# SF32LB52x register map
File version: 1.0
CPU: CM33 r0p1, little endian, MPU, FPU, 3 interrupt priority bits
Registers are 32-bit, read-write, reset 0x0 unless marked. A register's access mark holds for its fields unless they carry their own. Offsets are from the block's base; [hi:lo] are bit positions; {n}, {i} and the like mark numbered series.

## LPSYS_AON
Base 0x40040000
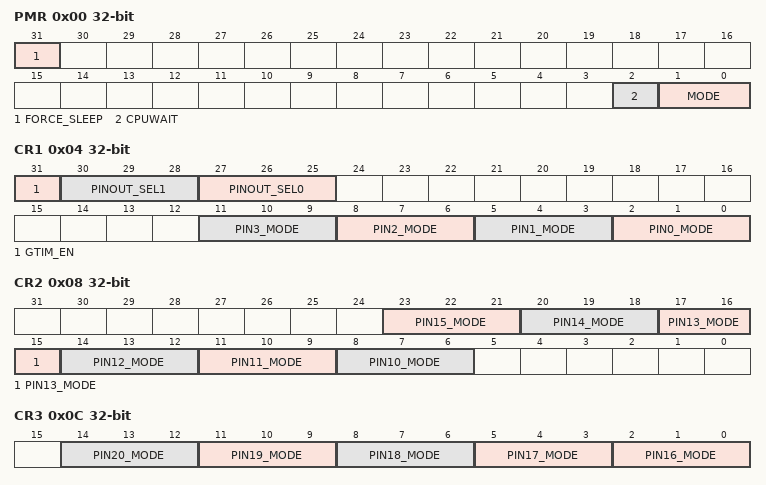
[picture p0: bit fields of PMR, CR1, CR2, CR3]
0x00 PMR — Power Mode Register
  [31] FORCE_SLEEP — Set 1 to force enter low power mode. Will be cleared automatically
  [2] CPUWAIT — Stall CPU out of reset. Should be cleared before LCPU run
  [1:0] MODE — Power Mode: 2'h0 - active/idle; 2'h1 - light sleep; 2'h2 - deep sleep; 2'h3 - standby
0x04 CR1 — Control Register 1
  [31] GTIM_EN — Enable global timer
  [30:28] PINOUT_SEL1 — for debug only
  [27:25] PINOUT_SEL0 — for debug only
  [11:9] PIN3_MODE — mode for wakeup PIN3 (PA27)
  [8:6] PIN2_MODE — mode for wakeup PIN2 (PA26)
  [5:3] PIN1_MODE — mode for wakeup PIN1 (PA25)
  [2:0] PIN0_MODE — mode for wakeup PIN0 (PA24) 0 - high level, 1 - low level, 2 - pos edge, 3 - neg edge, 4/5/6/7: pos or neg edge
0x08 CR2 — Control Register 2
  [3n-22:3n-24] PIN{n}_MODE (n=11..15) — mode for wakeup PIN{n} (PA{n+24})
  [8:6] PIN10_MODE — mode for wakeup PIN10 (PA34) 0 - high level, 1 - low level, 2 - pos edge, 3 - neg edge, 4/5/6/7: pos or neg edge
0x0C CR3 — Control Register 3
  [3n-46:3n-48] PIN{n}_MODE (n=17..20) — mode for wakeup PIN{n} (PA{n+24})
  [2:0] PIN16_MODE — mode for wakeup PIN16 (PA40) 0 - high level, 1 - low level, 2 - pos edge, 3 - neg edge, 4/5/6/7: pos or neg edge
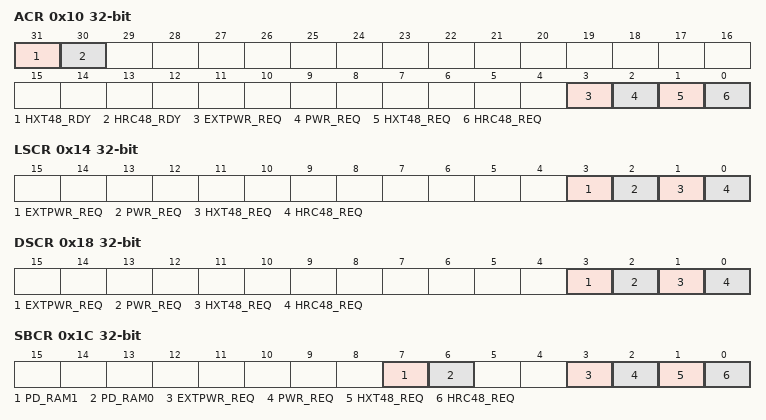
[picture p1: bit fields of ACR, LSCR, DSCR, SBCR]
0x10 ACR — Active Mode Control register
  [31] HXT48_RDY — Indicate hxt48 is ready
  [30] HRC48_RDY — Indicate hrc48 is ready
  [3] EXTPWR_REQ — for debug only
  [2] PWR_REQ — Request power during Active mode
  [1] HXT48_REQ — Request hxt48 in active mode
  [0] HRC48_REQ — Request hrc48 in active mode
0x14 LSCR — Light Sleep Ctrl Register
  [3] EXTPWR_REQ — for debug only
  [2] PWR_REQ — Request power during Light Sleep mode
  [1] HXT48_REQ — Request hxt48 in Light Sleep mode
  [0] HRC48_REQ — Request hrc48 in Light Sleep mode
0x18 DSCR — Deep Sleep Ctrl Register
  [3] EXTPWR_REQ — for debug only
  [2] PWR_REQ — Request power during Deep Sleep mode
  [1] HXT48_REQ — Request hxt48 in Deep Sleep mode
  [0] HRC48_REQ — Request hrc48 in Deep Sleep mode
0x1C SBCR — Standby Mode Ctrl Register
  [7] PD_RAM1 — for debug only
  [6] PD_RAM0 — for debug only
  [3] EXTPWR_REQ — for debug only
  [2] PWR_REQ — Request power during Standby mode
  [1] HXT48_REQ — Request hxt48 in Standby mode
  [0] HRC48_REQ — Request hrc48 in Standby mode
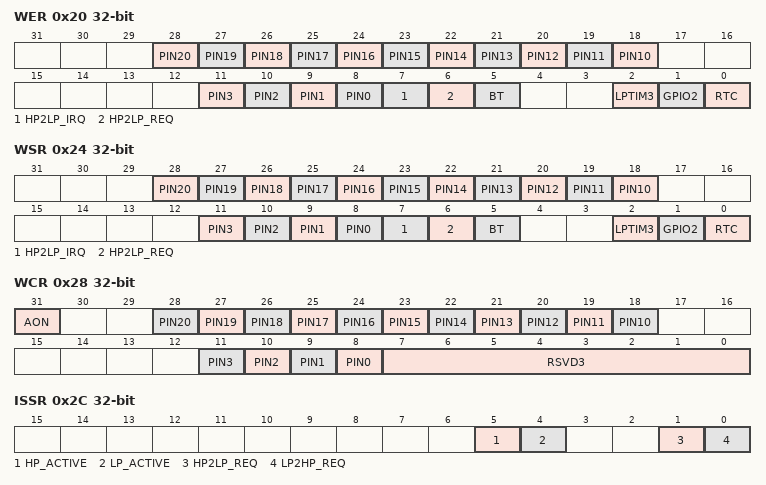
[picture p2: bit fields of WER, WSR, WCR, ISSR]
0x20 WER — Wakeup Enable register
  [n+8] PIN{n} (n=10..20) — Set 1 to enable PA{n+24} as wakeup source
  [n+8] PIN{n} (n=0..3) — Set 1 to enable PA{n+24} as wakeup source
  [7] HP2LP_IRQ — Set 1 to enable MAILBOX1 as wakeup source
  [6] HP2LP_REQ — Set 1 to enable HPSYS request as wakeup source
  [5] BT — Set 1 to enable BT as wakeup source
  [2] LPTIM3 — Set 1 to enable LPTIM3 as wakeup source
  [1] GPIO2 — Set 1 to enable IO(PB) as wakeup source
  [0] RTC — Set 1 to enable RTC as wakeup source
0x24 WSR — Wakeup Status register
  [n+8] PIN{n} (n=10..20) — Indicates the wakeup status from PA{n+24} request. Note: the status is masked by WER
  [n+8] PIN{n} (n=0..3) — Indicates the wakeup status from PA{n+24} request. Note: the status is masked by WER
  [7] HP2LP_IRQ — Indicates the wakeup status from MAILBOX1. Note: the status is masked by WER
  [6] HP2LP_REQ — Indicates the wakeup status from HPSYS request. Note: the status is masked by WER
  [5] BT — Indicates the wakeup status from BT. Note: the status is masked by WER
  [2] LPTIM3 — Indicates the wakeup status from LPTIM3. Note: the status is masked by WER
  [1] GPIO2 — Indicates the wakeup status from IO(PB). Note: the status is masked by WER
  [0] RTC — Indicates the wakeup status from RTC. Note: the status is masked by WER
0x28 WCR — Wakeup Clear register
  [31] AON — Write 1 to clear the AON wakeup IRQ status
  [n+8] PIN{n} (n=10..20) — Write 1 to clear PA{n+24} wakeup source. Only valid if PIN wakeup is configured as edge trigger
  [n+8] PIN{n} (n=0..3) — Write 1 to clear PA{n+24} wakeup source. Only valid if PIN wakeup is configured as edge trigger
  [7:0] RSVD3 — Note: for RTC/GPIO/LPTIM/BT, clear the wakeup status directly in the corresponding module
0x2C ISSR — Inter System Status Register
  [5] HP_ACTIVE — read 1 indicates HPSYS is active
  [4] LP_ACTIVE — write 1 to indicates LPSYS is active
  [1] HP2LP_REQ — indicate HPSYS request exists
  [0] LP2HP_REQ — write 1 to request HPSYS to stay in active mode
0x30 TARGET — BT sleep time target
  [27:0] SLEEP_TARGET — bt sleep time target in cycles of clk_rtc
0x34 ACTUAL — BT actual sleep time
  [27:0] SLEEP_CNT — bt actual sleep time in cycles of clk_rtc. If not woken up by software or external interrupt, sleep_cnt counts up every clk_rtc cycle, until reaches sleep_target
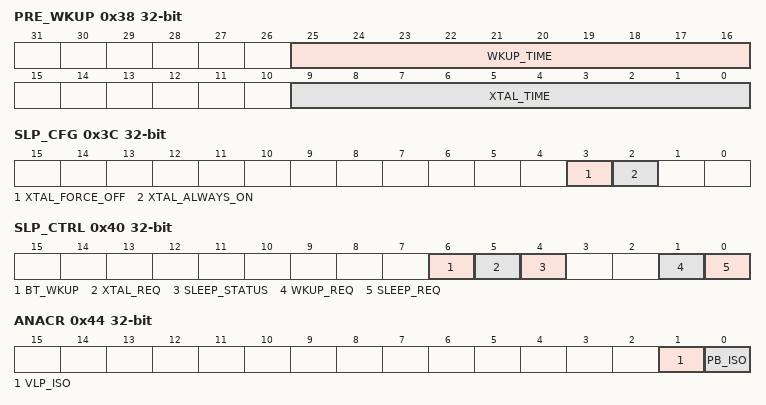
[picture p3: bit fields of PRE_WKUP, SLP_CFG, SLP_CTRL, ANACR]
0x38 PRE_WKUP — time before bt awake
  [25:16] WKUP_TIME — cycles of clk_rtc for LPSYS ready before bt awake.
  [9:0] XTAL_TIME — cycles of clk_rtc for hxt48 ready before bt awake.
0x3C SLP_CFG — BT sleep configuration
  [3] XTAL_FORCE_OFF — for debug only
  [2] XTAL_ALWAYS_ON — for debug only
0x40 SLP_CTRL — BT sleep control
  [6] BT_WKUP — bt wakeup source. 1 means bt has not enter sleep or has enter wakeup procedure
  [5] XTAL_REQ — xtal request status. 1 means bt is requiring xtal.
  [4] SLEEP_STATUS — bt sleep status. 1 means bt is sleeping and sleep_cnt is counting up
  [1] WKUP_REQ — software request to wakeup bt. Will be cleared automatically
  [0] SLEEP_REQ — bt sleep request. Will be cleared automatically
0x44 ANACR — Analog Control Register
  [1] VLP_ISO — Set 1 to force off all LPSYS related analog modules
  [0] PB_ISO — Set 1 to force IO(PB) into retention mode
0x48 GTIMR — Global Timer Register
  [31:0] CNT — Global timer value
0x4C RESERVE0 — Reserved Register 0
  [31:0] DATA — for debug only
0x50 RESERVE1 — Reserved Register 1
  [31:0] DATA — for debug only
0x100 SPR — Stack Pointer Register
  [31:0] SP — LCPU stack pointer address
0x104 PCR — Pointer Counter Register
  [31:0] PC — LCPU PC pointer address
